# CTRL_MMR0_CFG0 register map
Vendor: Texas Instruments
Peripheral module from a debugger description file (folder am243x).
Registers are 32-bit, read-write, reset 0x0 unless marked. A register's access mark holds for its fields unless they carry their own. Offsets are as the file gives them; lines under a group give offsets from that group; [hi:lo] are bit positions; {n}, {i} and the like mark numbered series; 'fields as' and 'values as' point back to an identical list; <NAME> marks a mode.

## CTRL_MMR0_CFG0
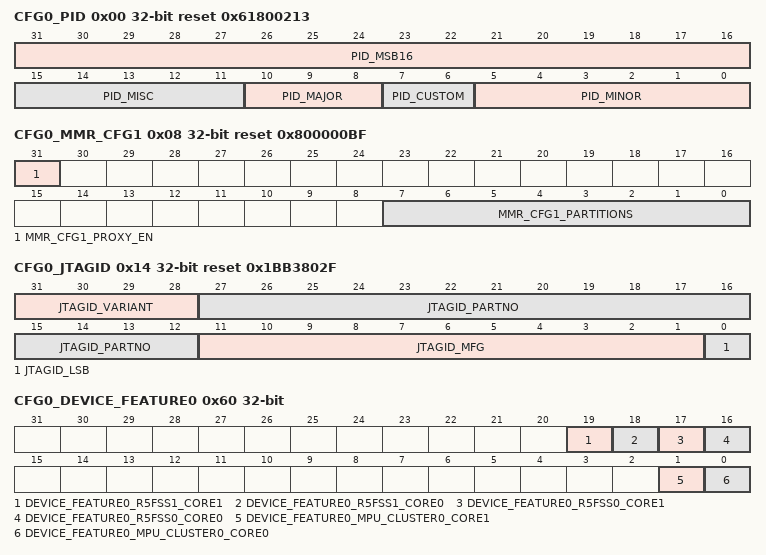
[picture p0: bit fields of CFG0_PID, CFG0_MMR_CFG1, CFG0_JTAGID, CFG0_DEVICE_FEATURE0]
0x00 CFG0_PID ro reset 0x61800213
  [31:16] PID_MSB16, [15:11] PID_MISC, [10:8] PID_MAJOR, [7:6] PID_CUSTOM, [5:0] PID_MINOR
0x08 CFG0_MMR_CFG1 ro reset 0x800000BF
  [31] MMR_CFG1_PROXY_EN — Proxy addressing activated
  [7:0] MMR_CFG1_PARTITIONS — Indicates present partitions
0x14 CFG0_JTAGID ro reset 0x1BB3802F
  [31:28] JTAGID_VARIANT — Used to indicate new PGs
  [27:12] JTAGID_PARTNO — Part number for boundary scan
  [11:1] JTAGID_MFG — Indicates manufacturer
  [0] JTAGID_LSB — Always 1
0x18 CFG0_JTAG_USER_ID ro
  [31:0] JTAG_USER_ID_USERCODE — Device information
0x30 CFG0_MAIN_DEVSTAT
  [15:0] MAIN_DEVSTAT_BOOTMODE — Specifies the device Primary and Backup boot media.
0x34 CFG0_MAIN_BOOTCFG ro
  [15:0] MAIN_BOOTCFG_BOOTMODE — Specifies the device Primary and Backup boot media as latched at PORz
0x44 CFG0_BOOT_PROGRESS
  [31:0] BOOT_PROGRESS_PROGRESS — Written by ROM to indicate boot progression. Values and their meaning are determined by the ROM.
0x60 CFG0_DEVICE_FEATURE0 ro
  [19] DEVICE_FEATURE0_R5FSS1_CORE1 — R5FSS1 CPU1 activated when set. CPU0 must also be activated.
  [18] DEVICE_FEATURE0_R5FSS1_CORE0 — R5FSS1 CPU0 activated when set.
  [17] DEVICE_FEATURE0_R5FSS0_CORE1 — R5FSS0 CPU1 activated when set. CPU0 must also be activated.
  [16] DEVICE_FEATURE0_R5FSS0_CORE0 — R5FSS0 CPU0 activated when set.
  [1] DEVICE_FEATURE0_MPU_CLUSTER0_CORE1 — MPU Cluster0 Core 1 is activated when set
  [0] DEVICE_FEATURE0_MPU_CLUSTER0_CORE0 — MPU Cluster0 Core 0 is activated when set
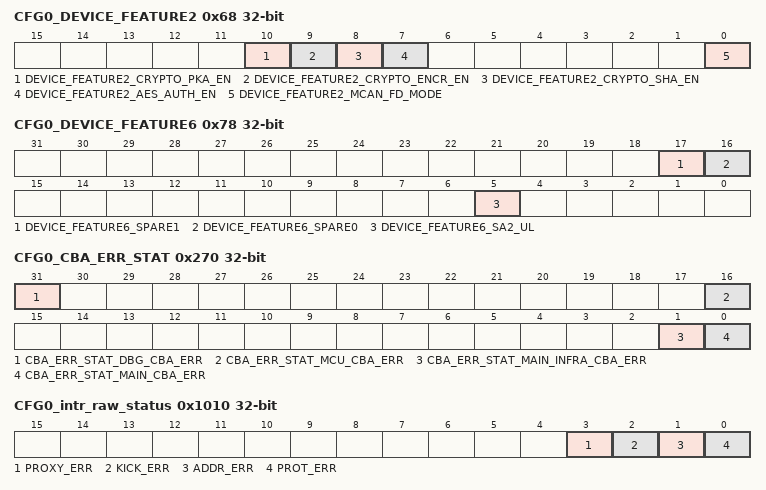
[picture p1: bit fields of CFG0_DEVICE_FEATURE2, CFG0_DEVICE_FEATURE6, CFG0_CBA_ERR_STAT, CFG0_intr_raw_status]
0x68 CFG0_DEVICE_FEATURE2 ro
  [10] DEVICE_FEATURE2_CRYPTO_PKA_EN — SA2_UL Crypto Module PKA activated
  [9] DEVICE_FEATURE2_CRYPTO_ENCR_EN — SA2_UL Crypto Module AES/3DES/DBRG activated
  [8] DEVICE_FEATURE2_CRYPTO_SHA_EN — SA2_UL Crypto Module SHA/MD5 activated
  [7] DEVICE_FEATURE2_AES_AUTH_EN — AES authentication is activated in FlashSS and DMSC when set
  [0] DEVICE_FEATURE2_MCAN_FD_MODE — FD mode is supported on MCAN[1:0] when set
0x78 CFG0_DEVICE_FEATURE6 access not given
  [17] DEVICE_FEATURE6_SPARE1 ro — Spare1 LPSC is activated when set
  [16] DEVICE_FEATURE6_SPARE0 ro — Spare0 LPSC is activated when set
  [5] DEVICE_FEATURE6_SA2_UL ro — MAIN domain security accelerator is activated when set
0x200 CFG0_MAC_ID0
  [31:0] MAC_ID0_MACID_LO — 32 lsbs of MAC address
0x204 CFG0_MAC_ID1
  [15:0] MAC_ID1_MACID_HI — 16 msbs of MAC address
0x210 CFG0_PCI_DEVICE_ID0 reset 0xB010104C
  [31:0] PCI_DEVICE_ID0_ID0 — ROM can optionally update this register with a 32 bit value from Customer OTP.
0x214 CFG0_PCI_DEVICE_ID1 reset 0xB010104C
  [31:0] PCI_DEVICE_ID1_ID1 — ROM can optionally update this register with a 32 bit value from Customer OTP.
0x220 CFG0_USB_DEVICE_ID0 reset 0x61650451
  [31:0] USB_DEVICE_ID0_ID0 — ROM can optionally update this register with a 32 bit value from Customer OTP.
0x224 CFG0_USB_DEVICE_ID1 reset 0x61650451
  [31:0] USB_DEVICE_ID1_ID1 — ROM can optionally update this register with a 32 bit value from Customer OTP.
{0x230+4i} CFG0_GP_SW{i} ro (i=0..2)
  [31:0] GP_SW{i}_VAL — general purpose value
0x23C CFG0_GP_SW3 ro
  [3:0] GP_SW3_VAL — general purpose value
0x270 CFG0_CBA_ERR_STAT ro
  [31] CBA_ERR_STAT_DBG_CBA_ERR, [16] CBA_ERR_STAT_MCU_CBA_ERR, [1] CBA_ERR_STAT_MAIN_INFRA_CBA_ERR, [0] CBA_ERR_STAT_MAIN_CBA_ERR
{0x1008+0x4000*i} CFG0_LOCK{i}_KICK0 (i=0..6)
  [31:0] LOCK{i}_KICK0 — - KICK0 component
{0x100C+0x4000*i} CFG0_LOCK{i}_KICK1 (i=0..6)
  [31:0] LOCK{i}_KICK1 — - KICK1 component
0x1010 CFG0_intr_raw_status access not given
  [3] PROXY_ERR — Proxy0 access violation error. Raw status is read. Write a 1 to set the status. Writing a 0 has no effect. (access R/W1TS)
  [2] KICK_ERR — Kick access violation error. Raw status is read. Write a 1 to set the status. Writing a 0 has no effect. (access R/W1TS)
  [1] ADDR_ERR — Addressing violation error. Raw status is read. Write a 1 to set the status. Writing a 0 has no effect. (access R/W1TS)
  [0] PROT_ERR — Protection violation error. Raw status is read. Write a 1 to set the status. Writing a 0 has no effect. (access R/W1TS)
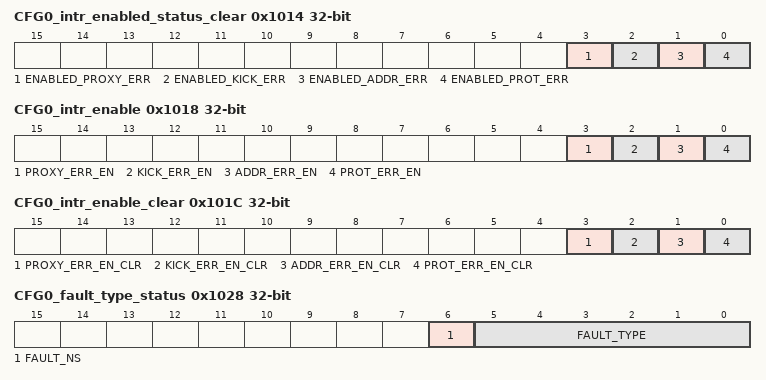
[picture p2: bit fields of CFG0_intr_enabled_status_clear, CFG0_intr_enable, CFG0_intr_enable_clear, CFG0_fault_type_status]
0x1014 CFG0_intr_enabled_status_clear access not given
  [3] ENABLED_PROXY_ERR — Proxy0 access violation error. Enabled status is read. Write a 1 to clear the status. Writing a 0 has no effect. (access R/W1TC)
  [2] ENABLED_KICK_ERR — Kick access violation error. Enabled status is read. Write a 1 to clear the status. Writing a 0 has no effect. (access R/W1TC)
  [1] ENABLED_ADDR_ERR — Addressing violation error. Enabled status is read. Write a 1 to clear the status. Writing a 0 has no effect. (access R/W1TC)
  [0] ENABLED_PROT_ERR — Protection violation error. Enabled status is read. Write a 1 to clear the status. Writing a 0 has no effect. (access R/W1TC)
0x1018 CFG0_intr_enable access not given
  [3] PROXY_ERR_EN — Proxy0 access violation error enable. Write a 1 to set the enable. Writing a 0 has no effect. (access R/W1TS)
  [2] KICK_ERR_EN — Kick access violation error enable. Write a 1 to set the enable. Writing a 0 has no effect. (access R/W1TS)
  [1] ADDR_ERR_EN — Addressing violation error enable. Write a 1 to set the enable. Writing a 0 has no effect. (access R/W1TS)
  [0] PROT_ERR_EN — Protection violation error enable. Write a 1 to set the enable. Writing a 0 has no effect. (access R/W1TS)
0x101C CFG0_intr_enable_clear access not given
  [3] PROXY_ERR_EN_CLR — Proxy0 access violation error enable clear. Write a 1 to clear the enable. Writing a 0 has no effect. (access R/W1TC)
  [2] KICK_ERR_EN_CLR — Kick access violation error enable clear. Write a 1 to clear the enable. Writing a 0 has no effect. (access R/W1TC)
  [1] ADDR_ERR_EN_CLR — Addressing violation error enable clear. Write a 1 to clear the enable. Writing a 0 has no effect. (access R/W1TC)
  [0] PROT_ERR_EN_CLR — Protection violation error enable clear. Write a 1 to clear the enable. Writing a 0 has no effect. (access R/W1TC)
0x1020 CFG0_eoi
  [7:0] EOI_VECTOR — EOI vector value. Write this with interrupt distribution value in the chip.
0x1024 CFG0_fault_address ro
  [31:0] FAULT_ADDR — Fault Address.
0x1028 CFG0_fault_type_status ro
  [6] FAULT_NS — Non-secure access.
  [5:0] FAULT_TYPE — Fault Type 10_0000 = Supervisor read fault - priv = 1 dir = 1 dtype != 1 01_0000 = Supervisor write fault - priv = 1 dir = 0 00_1000 = Supervisor execute fault - priv = 1 dir = 1 dtype = 1 00_0100 = User read fault - priv = 0 dir = 1 dtype = 1 00_0010 = User write fault - priv = 0 dir = 0 00_0001 = User execute fault - priv = 0 dir = 1 dtype = 1 00_0000 = No fault
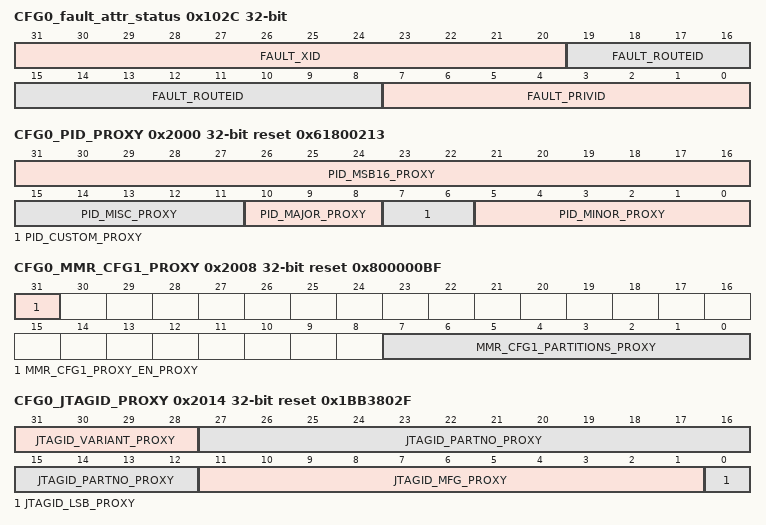
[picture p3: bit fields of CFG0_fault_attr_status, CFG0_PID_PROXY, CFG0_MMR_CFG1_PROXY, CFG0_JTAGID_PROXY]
0x102C CFG0_fault_attr_status ro
  [31:20] FAULT_XID — XID.
  [19:8] FAULT_ROUTEID — Route ID.
  [7:0] FAULT_PRIVID — Privilege ID.
0x1030 CFG0_fault_clear wo
  [0] FAULT_CLR — Fault clear. Writing a 1 clears the current fault. Writing a 0 has no effect.
{0x1100+4i} CFG0_CLAIMREG_P0_R{i}_READONLY ro (i=0..6)
  [31:0] CLAIMREG_P0_R{i}_READONLY — Claim bits for Partition 0
0x2000 CFG0_PID_PROXY ro reset 0x61800213
  [31:16] PID_MSB16_PROXY, [15:11] PID_MISC_PROXY, [10:8] PID_MAJOR_PROXY, [7:6] PID_CUSTOM_PROXY, [5:0] PID_MINOR_PROXY
0x2008 CFG0_MMR_CFG1_PROXY ro reset 0x800000BF
  [31] MMR_CFG1_PROXY_EN_PROXY — Proxy addressing activated
  [7:0] MMR_CFG1_PARTITIONS_PROXY — Indicates present partitions
0x2014 CFG0_JTAGID_PROXY ro reset 0x1BB3802F
  [31:28] JTAGID_VARIANT_PROXY — Used to indicate new PGs
  [27:12] JTAGID_PARTNO_PROXY — Part number for boundary scan
  [11:1] JTAGID_MFG_PROXY — Indicates manufacturer
  [0] JTAGID_LSB_PROXY — Always 1
0x2018 CFG0_JTAG_USER_ID_PROXY ro
  [31:0] JTAG_USER_ID_USERCODE_PROXY — Device information
0x2030 CFG0_MAIN_DEVSTAT_PROXY
  [15:0] MAIN_DEVSTAT_BOOTMODE_PROXY — Specifies the device Primary and Backup boot media.
0x2034 CFG0_MAIN_BOOTCFG_PROXY ro
  [15:0] MAIN_BOOTCFG_BOOTMODE_PROXY — Specifies the device Primary and Backup boot media as latched at PORz
0x2044 CFG0_BOOT_PROGRESS_PROXY
  [31:0] BOOT_PROGRESS_PROGRESS_PROXY — Written by ROM to indicate boot progression. Values and their meaning are determined by the ROM.
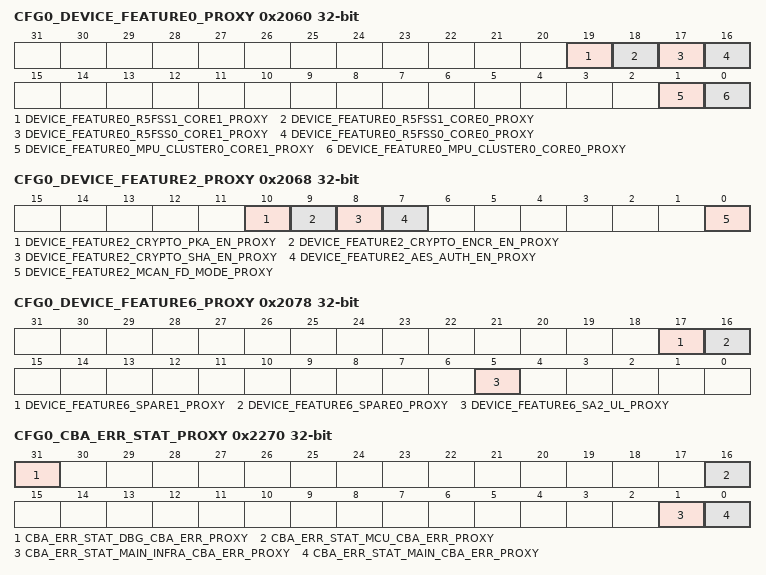
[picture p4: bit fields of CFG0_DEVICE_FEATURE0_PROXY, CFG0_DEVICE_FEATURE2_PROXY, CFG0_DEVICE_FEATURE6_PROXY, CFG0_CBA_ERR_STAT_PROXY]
0x2060 CFG0_DEVICE_FEATURE0_PROXY ro
  [19] DEVICE_FEATURE0_R5FSS1_CORE1_PROXY — R5FSS1 CPU1 activated when set. CPU0 must also be activated.
  [18] DEVICE_FEATURE0_R5FSS1_CORE0_PROXY — R5FSS1 CPU0 activated when set.
  [17] DEVICE_FEATURE0_R5FSS0_CORE1_PROXY — R5FSS0 CPU1 activated when set. CPU0 must also be activated.
  [16] DEVICE_FEATURE0_R5FSS0_CORE0_PROXY — R5FSS0 CPU0 activated when set.
  [1] DEVICE_FEATURE0_MPU_CLUSTER0_CORE1_PROXY — MPU Cluster0 Core 1 is activated when set
  [0] DEVICE_FEATURE0_MPU_CLUSTER0_CORE0_PROXY — MPU Cluster0 Core 0 is activated when set
0x2068 CFG0_DEVICE_FEATURE2_PROXY ro
  [10] DEVICE_FEATURE2_CRYPTO_PKA_EN_PROXY — SA2_UL Crypto Module PKA activated
  [9] DEVICE_FEATURE2_CRYPTO_ENCR_EN_PROXY — SA2_UL Crypto Module AES/3DES/DBRG activated
  [8] DEVICE_FEATURE2_CRYPTO_SHA_EN_PROXY — SA2_UL Crypto Module SHA/MD5 activated
  [7] DEVICE_FEATURE2_AES_AUTH_EN_PROXY — AES authentication is activated in FlashSS and DMSC when set
  [0] DEVICE_FEATURE2_MCAN_FD_MODE_PROXY — FD mode is supported on MCAN[1:0] when set
0x2078 CFG0_DEVICE_FEATURE6_PROXY access not given
  [17] DEVICE_FEATURE6_SPARE1_PROXY ro — Spare1 LPSC is activated when set
  [16] DEVICE_FEATURE6_SPARE0_PROXY ro — Spare0 LPSC is activated when set
  [5] DEVICE_FEATURE6_SA2_UL_PROXY ro — MAIN domain security accelerator is activated when set
0x2200 CFG0_MAC_ID0_PROXY
  [31:0] MAC_ID0_MACID_LO_PROXY — 32 lsbs of MAC address
0x2204 CFG0_MAC_ID1_PROXY
  [15:0] MAC_ID1_MACID_HI_PROXY — 16 msbs of MAC address
0x2210 CFG0_PCI_DEVICE_ID0_PROXY reset 0xB010104C
  [31:0] PCI_DEVICE_ID0_ID0_PROXY — ROM can optionally update this register with a 32 bit value from Customer OTP.
0x2214 CFG0_PCI_DEVICE_ID1_PROXY reset 0xB010104C
  [31:0] PCI_DEVICE_ID1_ID1_PROXY — ROM can optionally update this register with a 32 bit value from Customer OTP.
0x2220 CFG0_USB_DEVICE_ID0_PROXY reset 0x61650451
  [31:0] USB_DEVICE_ID0_ID0_PROXY — ROM can optionally update this register with a 32 bit value from Customer OTP.
0x2224 CFG0_USB_DEVICE_ID1_PROXY reset 0x61650451
  [31:0] USB_DEVICE_ID1_ID1_PROXY — ROM can optionally update this register with a 32 bit value from Customer OTP.
{0x2230+4i} CFG0_GP_SW{i}_PROXY ro (i=0..2)
  [31:0] GP_SW{i}_VAL_PROXY — general purpose value
0x223C CFG0_GP_SW3_PROXY ro
  [3:0] GP_SW3_VAL_PROXY — general purpose value
0x2270 CFG0_CBA_ERR_STAT_PROXY ro
  [31] CBA_ERR_STAT_DBG_CBA_ERR_PROXY, [16] CBA_ERR_STAT_MCU_CBA_ERR_PROXY, [1] CBA_ERR_STAT_MAIN_INFRA_CBA_ERR_PROXY, [0] CBA_ERR_STAT_MAIN_CBA_ERR_PROXY
{0x3008+0x4000*i} CFG0_LOCK{i}_KICK0_PROXY (i=0..6)
  [31:0] LOCK{i}_KICK0_PROXY — - KICK0 component
{0x300C+0x4000*i} CFG0_LOCK{i}_KICK1_PROXY (i=0..6)
  [31:0] LOCK{i}_KICK1_PROXY — - KICK1 component
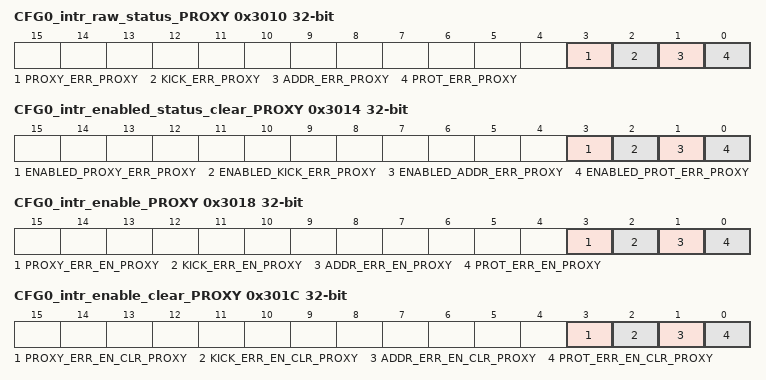
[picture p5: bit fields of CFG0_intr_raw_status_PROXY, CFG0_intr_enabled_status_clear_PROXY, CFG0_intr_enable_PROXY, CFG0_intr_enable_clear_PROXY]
0x3010 CFG0_intr_raw_status_PROXY access not given
  [3] PROXY_ERR_PROXY — Proxy0 access violation error. Raw status is read. Write a 1 to set the status. Writing a 0 has no effect. (access R/W1TS)
  [2] KICK_ERR_PROXY — Kick access violation error. Raw status is read. Write a 1 to set the status. Writing a 0 has no effect. (access R/W1TS)
  [1] ADDR_ERR_PROXY — Addressing violation error. Raw status is read. Write a 1 to set the status. Writing a 0 has no effect. (access R/W1TS)
  [0] PROT_ERR_PROXY — Protection violation error. Raw status is read. Write a 1 to set the status. Writing a 0 has no effect. (access R/W1TS)
0x3014 CFG0_intr_enabled_status_clear_PROXY access not given
  [3] ENABLED_PROXY_ERR_PROXY — Proxy0 access violation error. Enabled status is read. Write a 1 to clear the status. Writing a 0 has no effect. (access R/W1TC)
  [2] ENABLED_KICK_ERR_PROXY — Kick access violation error. Enabled status is read. Write a 1 to clear the status. Writing a 0 has no effect. (access R/W1TC)
  [1] ENABLED_ADDR_ERR_PROXY — Addressing violation error. Enabled status is read. Write a 1 to clear the status. Writing a 0 has no effect. (access R/W1TC)
  [0] ENABLED_PROT_ERR_PROXY — Protection violation error. Enabled status is read. Write a 1 to clear the status. Writing a 0 has no effect. (access R/W1TC)
0x3018 CFG0_intr_enable_PROXY access not given
  [3] PROXY_ERR_EN_PROXY — Proxy0 access violation error enable. Write a 1 to set the enable. Writing a 0 has no effect. (access R/W1TS)
  [2] KICK_ERR_EN_PROXY — Kick access violation error enable. Write a 1 to set the enable. Writing a 0 has no effect. (access R/W1TS)
  [1] ADDR_ERR_EN_PROXY — Addressing violation error enable. Write a 1 to set the enable. Writing a 0 has no effect. (access R/W1TS)
  [0] PROT_ERR_EN_PROXY — Protection violation error enable. Write a 1 to set the enable. Writing a 0 has no effect. (access R/W1TS)
0x301C CFG0_intr_enable_clear_PROXY access not given
  [3] PROXY_ERR_EN_CLR_PROXY — Proxy0 access violation error enable clear. Write a 1 to clear the enable. Writing a 0 has no effect. (access R/W1TC)
  [2] KICK_ERR_EN_CLR_PROXY — Kick access violation error enable clear. Write a 1 to clear the enable. Writing a 0 has no effect. (access R/W1TC)
  [1] ADDR_ERR_EN_CLR_PROXY — Addressing violation error enable clear. Write a 1 to clear the enable. Writing a 0 has no effect. (access R/W1TC)
  [0] PROT_ERR_EN_CLR_PROXY — Protection violation error enable clear. Write a 1 to clear the enable. Writing a 0 has no effect. (access R/W1TC)
0x3020 CFG0_eoi_PROXY
  [7:0] EOI_VECTOR_PROXY — EOI vector value. Write this with interrupt distribution value in the chip.
0x3024 CFG0_fault_address_PROXY ro
  [31:0] FAULT_ADDR_PROXY — Fault Address.
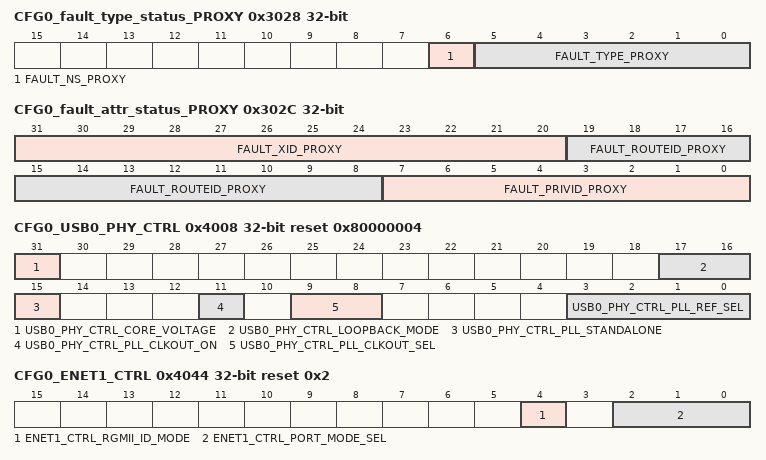
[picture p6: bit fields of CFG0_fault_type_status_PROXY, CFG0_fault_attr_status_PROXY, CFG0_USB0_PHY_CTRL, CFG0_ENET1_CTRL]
0x3028 CFG0_fault_type_status_PROXY ro
  [6] FAULT_NS_PROXY — Non-secure access.
  [5:0] FAULT_TYPE_PROXY — Fault Type 10_0000 = Supervisor read fault - priv = 1 dir = 1 dtype != 1 01_0000 = Supervisor write fault - priv = 1 dir = 0 00_1000 = Supervisor execute fault - priv = 1 dir = 1 dtype = 1 00_0100 = User read fault - priv = 0 dir = 1 dtype = 1 00_0010 = User write fault - priv = 0 dir = 0 00_0001 = User execute fault - priv = 0 dir = 1 dtype = 1 00_0000 = No fault
0x302C CFG0_fault_attr_status_PROXY ro
  [31:20] FAULT_XID_PROXY — XID.
  [19:8] FAULT_ROUTEID_PROXY — Route ID.
  [7:0] FAULT_PRIVID_PROXY — Privilege ID.
0x3030 CFG0_fault_clear_PROXY wo
  [0] FAULT_CLR_PROXY — Fault clear. Writing a 1 clears the current fault. Writing a 0 has no effect.
{0x3100+4i} CFG0_CLAIMREG_P0_R{i} (i=0..6)
  [31:0] CLAIMREG_P0_R{i} — Claim bits for Partition 0
0x4008 CFG0_USB0_PHY_CTRL reset 0x80000004
  [31] USB0_PHY_CTRL_CORE_VOLTAGE — Selects the USB PHY Core Voltage
  [17:16] USB0_PHY_CTRL_LOOPBACK_MODE — Activates USB0 PHY loopback operation
  [15] USB0_PHY_CTRL_PLL_STANDALONE — Activates USB0 PHY as a standalone PLL
  [11] USB0_PHY_CTRL_PLL_CLKOUT_ON — Controls USB0 PLL clock output
  [9:8] USB0_PHY_CTRL_PLL_CLKOUT_SEL — Selects the frequency of the USB0 PLL output clock
  [3:0] USB0_PHY_CTRL_PLL_REF_SEL — Indicates the frequency of the REF_CLOCK input used by the USB PLL. This value should match the frequency value of either the HFOSC0 or HFOSC1 oscillator as selected by the USB0_CLKSEL register
0x4044 CFG0_ENET1_CTRL reset 0x2
  [4] ENET1_CTRL_RGMII_ID_MODE — Port1 RGMII internal transmit delay selection
  [2:0] ENET1_CTRL_PORT_MODE_SEL — Selects Ethernet switch Port1 interface
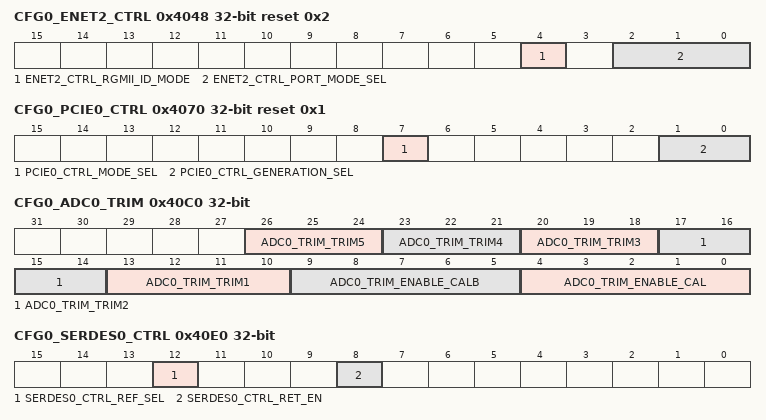
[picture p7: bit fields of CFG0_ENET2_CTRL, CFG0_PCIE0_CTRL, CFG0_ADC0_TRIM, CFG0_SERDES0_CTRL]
0x4048 CFG0_ENET2_CTRL reset 0x2
  [4] ENET2_CTRL_RGMII_ID_MODE — Port2 RGMII internal transmit delay selection
  [2:0] ENET2_CTRL_PORT_MODE_SEL — Selects Ethernet switch Port2 interface
0x4070 CFG0_PCIE0_CTRL reset 0x1
  [7] PCIE0_CTRL_MODE_SEL — Selects the operating mode
  [1:0] PCIE0_CTRL_GENERATION_SEL — Configures the PCIe generation support in the PCIe capabilities linked-list
0x4080 CFG0_SERDES0_LN0_CTRL
  [1:0] SERDES0_LN0_CTRL_LANE_FUNC_SEL — Selects the SERDES0 lane0 function
0x40C0 CFG0_ADC0_TRIM
  [26:24] ADC0_TRIM_TRIM5 — Trims Nonlinearities from ADC
  [23:21] ADC0_TRIM_TRIM4 — Trims Nonlinearities from ADC
  [20:18] ADC0_TRIM_TRIM3 — Trims Nonlinearities from ADC
  [17:14] ADC0_TRIM_TRIM2 — Trims Nonlinearities from ADC
  [13:10] ADC0_TRIM_TRIM1 — Trims Nonlinearities from ADC
  [9:5] ADC0_TRIM_ENABLE_CALB — Trims Nonlinearities from ADC
  [4:0] ADC0_TRIM_ENABLE_CAL — Trims Nonlinearities from ADC
0x40E0 CFG0_SERDES0_CTRL
  [12] SERDES0_CTRL_REF_SEL — REFCLK output select
  [8] SERDES0_CTRL_RET_EN — Retention activate
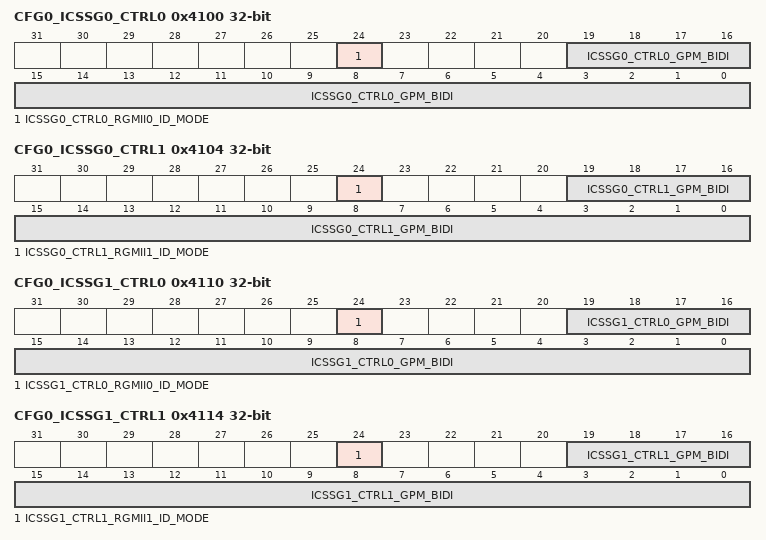
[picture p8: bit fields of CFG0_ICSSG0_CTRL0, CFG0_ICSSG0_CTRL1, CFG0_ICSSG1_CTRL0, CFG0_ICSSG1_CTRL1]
0x4100 CFG0_ICSSG0_CTRL0
  [24] ICSSG0_CTRL0_RGMII0_ID_MODE — Controls the ICSS_G0 RGMII0 port internal transmit delay
  [19:0] ICSSG0_CTRL0_GPM_BIDI — Controls operation of the ICSS_G0 PRU0_GPO pins. Each bit n controls the corresponding PRG0_PRU0GPOn I/O
0x4104 CFG0_ICSSG0_CTRL1
  [24] ICSSG0_CTRL1_RGMII1_ID_MODE — Controls the ICSS_G0 RGMII1 port internal transmit delay
  [19:0] ICSSG0_CTRL1_GPM_BIDI — Controls operation of the ICSS_G0 PRU1_GPO pins. Each bit n controls the corresponding PRG0_PRU1GPOn I/O
0x4110 CFG0_ICSSG1_CTRL0
  [24] ICSSG1_CTRL0_RGMII0_ID_MODE — Controls the ICSS_G1 RGMII0 port internal transmit delay
  [19:0] ICSSG1_CTRL0_GPM_BIDI — Controls operation of the ICSS_G1 PRU0_GPO pins. Each bit n controls the corresponding PRG1_PRU0GPOn I/O
0x4114 CFG0_ICSSG1_CTRL1
  [24] ICSSG1_CTRL1_RGMII1_ID_MODE — Controls the ICSS_G1 RGMII1 port internal transmit delay
  [19:0] ICSSG1_CTRL1_GPM_BIDI — Controls operation of the ICSS_G1 PRU1_GPO pins. Each bit n controls the corresponding PRG1_PRU1GPOn I/O
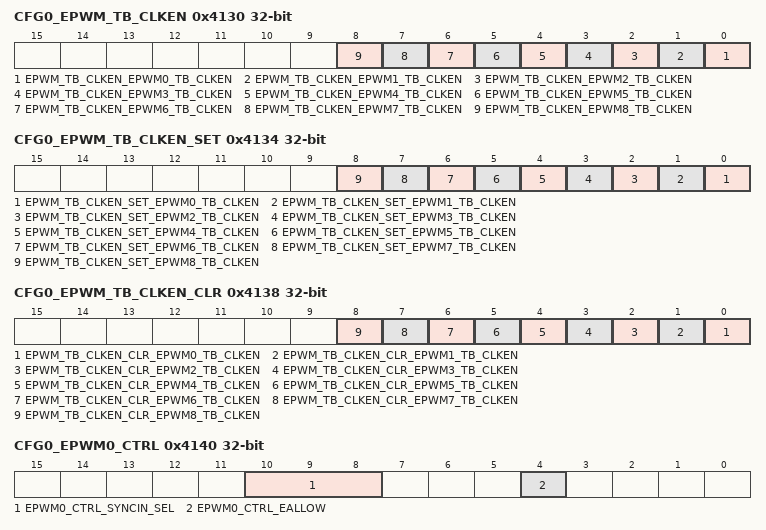
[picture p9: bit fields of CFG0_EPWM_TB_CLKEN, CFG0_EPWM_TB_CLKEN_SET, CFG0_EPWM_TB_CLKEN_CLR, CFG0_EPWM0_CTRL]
0x4130 CFG0_EPWM_TB_CLKEN
  [n] EPWM_TB_CLKEN_EPWM{n}_TB_CLKEN (n=0..8) — Activates Timebase Clock of EPWM{n} When Set
0x4134 CFG0_EPWM_TB_CLKEN_SET access not given
  [n] EPWM_TB_CLKEN_SET_EPWM{n}_TB_CLKEN (n=0..8) — Writing One Activates Timebase Clock of EPWM{n} (access R/W1TS)
0x4138 CFG0_EPWM_TB_CLKEN_CLR access not given
  [n] EPWM_TB_CLKEN_CLR_EPWM{n}_TB_CLKEN (n=0..8) — Writing One Deactivates Timebase Clock of EPWM{n} (access R/W1TC)
0x4140 CFG0_EPWM0_CTRL
  [10:8] EPWM0_CTRL_SYNCIN_SEL — Selects the source of the EPWM0 synchronization input
  [4] EPWM0_CTRL_EALLOW — Activate write access to EPWM tripzone registers
0x4144 CFG0_EPWM1_CTRL
  [4] EPWM1_CTRL_EALLOW — Activate write access to EPWM tripzone registers
0x4148 CFG0_EPWM2_CTRL
  [4] EPWM2_CTRL_EALLOW — Activate write access to EPWM tripzone registers
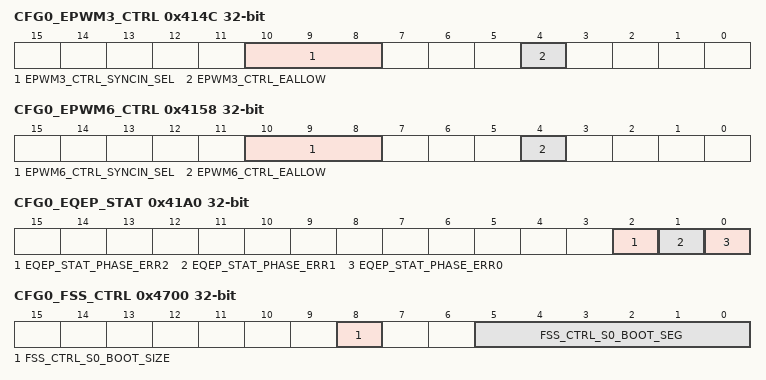
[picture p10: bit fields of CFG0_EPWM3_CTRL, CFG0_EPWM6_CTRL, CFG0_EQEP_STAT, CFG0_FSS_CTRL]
0x414C CFG0_EPWM3_CTRL
  [10:8] EPWM3_CTRL_SYNCIN_SEL — Selects the source of the EPWM3 synchronization input
  [4] EPWM3_CTRL_EALLOW — Activate write access to EPWM tripzone registers
0x4150 CFG0_EPWM4_CTRL
  [4] EPWM4_CTRL_EALLOW — Activate write access to EPWM tripzone registers
0x4154 CFG0_EPWM5_CTRL
  [4] EPWM5_CTRL_EALLOW — Activate write access to EPWM tripzone registers
0x4158 CFG0_EPWM6_CTRL
  [10:8] EPWM6_CTRL_SYNCIN_SEL — Selects the source of the EPWM6 synchronization input
  [4] EPWM6_CTRL_EALLOW — Activate write access to EPWM tripzone registers
0x415C CFG0_EPWM7_CTRL
  [4] EPWM7_CTRL_EALLOW — Activate write access to EPWM tripzone registers
0x4160 CFG0_EPWM8_CTRL
  [4] EPWM8_CTRL_EALLOW — Activate write access to EPWM tripzone registers
0x4170 CFG0_SOCA_SEL
  [1:0] SOCA_SEL_SOCA_SEL — Selects the SOC A output source
0x4174 CFG0_SOCB_SEL
  [1:0] SOCB_SEL_SOCB_SEL — Selects the SOC B output source
{0x4180+4i} CFG0_EQEP{i}_CTRL (i=0..2)
  [4:0] EQEP{i}_CTRL_SOCA_SEL — Selects the source of SOCA input for EQEP{i}
0x41A0 CFG0_EQEP_STAT ro
  [2] EQEP_STAT_PHASE_ERR2 — EQEP2 Phase error status
  [1] EQEP_STAT_PHASE_ERR1 — EQEP1 Phase error status
  [0] EQEP_STAT_PHASE_ERR0 — EQEP0 Phase error status
0x41B4 CFG0_SDIO1_CTRL
  [4:0] SDIO1_CTRL_DRV_STR — Selects the SDIO drive strength
0x4204 CFG0_TIMER1_CTRL
  [8] TIMER1_CTRL_CASCADE_EN — Activates cascading of TIMER1 to TIMER0
0x420C CFG0_TIMER3_CTRL
  [8] TIMER3_CTRL_CASCADE_EN — Activates cascading of TIMER3 to TIMER2
0x4214 CFG0_TIMER5_CTRL
  [8] TIMER5_CTRL_CASCADE_EN — Activates cascading of TIMER5 to TIMER4
0x421C CFG0_TIMER7_CTRL
  [8] TIMER7_CTRL_CASCADE_EN — Activates cascading of TIMER7 to TIMER6
0x4224 CFG0_TIMER9_CTRL
  [8] TIMER9_CTRL_CASCADE_EN — Activates cascading of TIMER9 to TIMER8
0x422C CFG0_TIMER11_CTRL
  [8] TIMER11_CTRL_CASCADE_EN — Activates cascading of TIMER11 to TIMER10
0x42E0 CFG0_I2C0_CTRL
  [0] I2C0_CTRL_HS_MCS_EN — HS Mode controller current source activate.
0x4700 CFG0_FSS_CTRL
  [8] FSS_CTRL_S0_BOOT_SIZE — Selects the size of the boot block to be used for the S0 (OSPI0) flash interface
  [5:0] FSS_CTRL_S0_BOOT_SEG — Selects the boot block to be used for the S0 (OSPI0) flash interface. If the s0_boot_size is 128 MB then only bits [4:0] of this field are used. Care must be taken to account for the address translation as to not fall off or wrap the address of the flash. (e.g. if both ECC and authentication are activated for 64 MB boot, the highest valid block number is is 49, as sector 50 is only .2M Bytes in size.)
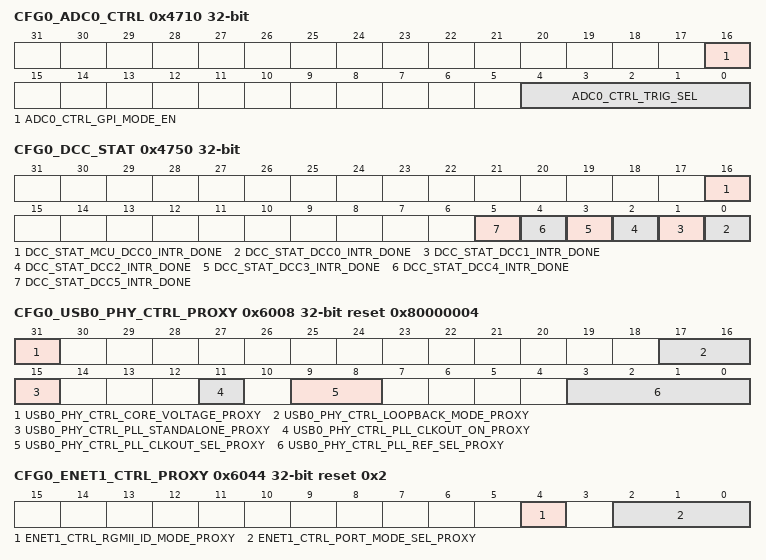
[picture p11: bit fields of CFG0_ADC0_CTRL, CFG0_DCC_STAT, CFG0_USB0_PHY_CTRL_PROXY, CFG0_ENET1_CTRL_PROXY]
0x4710 CFG0_ADC0_CTRL
  [16] ADC0_CTRL_GPI_MODE_EN — Activates ADC0 data pins to be used as general purpose inputs when set. This signal is tied to the en_dig_test input of MCU_ADC0
  [4:0] ADC0_CTRL_TRIG_SEL — Selects the source of the ADC hardware event trigger
0x4750 CFG0_DCC_STAT ro
  [16] DCC_STAT_MCU_DCC0_INTR_DONE — MCU_DCC0 Done Interrupt Status
  [n] DCC_STAT_DCC{n}_INTR_DONE (n=0..5) — DCC{n} Done Interrupt Status
{0x5100+4i} CFG0_CLAIMREG_P1_R{i}_READONLY ro (i=0..14)
  [31:0] CLAIMREG_P1_R{i}_READONLY — Claim bits for Partition 1
0x6008 CFG0_USB0_PHY_CTRL_PROXY reset 0x80000004
  [31] USB0_PHY_CTRL_CORE_VOLTAGE_PROXY — Selects the USB PHY Core Voltage
  [17:16] USB0_PHY_CTRL_LOOPBACK_MODE_PROXY — Activates USB0 PHY loopback operation
  [15] USB0_PHY_CTRL_PLL_STANDALONE_PROXY — Activates USB0 PHY as a standalone PLL
  [11] USB0_PHY_CTRL_PLL_CLKOUT_ON_PROXY — Controls USB0 PLL clock output
  [9:8] USB0_PHY_CTRL_PLL_CLKOUT_SEL_PROXY — Selects the frequency of the USB0 PLL output clock
  [3:0] USB0_PHY_CTRL_PLL_REF_SEL_PROXY — Indicates the frequency of the REF_CLOCK input used by the USB PLL. This value should match the frequency value of either the HFOSC0 or HFOSC1 oscillator as selected by the USB0_CLKSEL register
0x6044 CFG0_ENET1_CTRL_PROXY reset 0x2
  [4] ENET1_CTRL_RGMII_ID_MODE_PROXY — Port1 RGMII internal transmit delay selection
  [2:0] ENET1_CTRL_PORT_MODE_SEL_PROXY — Selects Ethernet switch Port1 interface
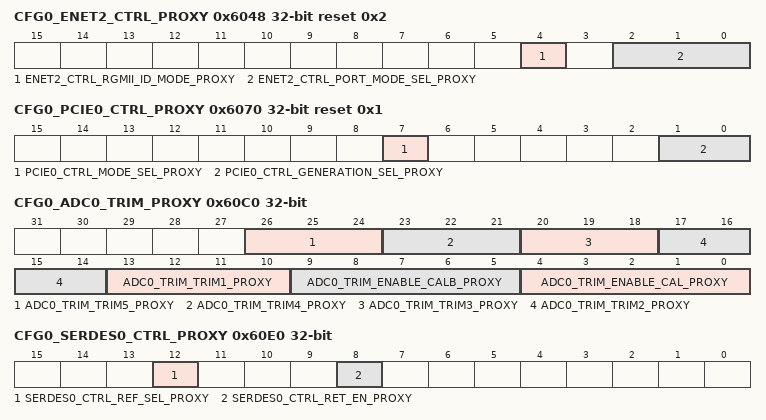
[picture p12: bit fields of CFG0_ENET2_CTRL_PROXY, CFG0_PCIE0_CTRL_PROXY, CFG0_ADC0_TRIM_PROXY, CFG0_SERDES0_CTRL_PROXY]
0x6048 CFG0_ENET2_CTRL_PROXY reset 0x2
  [4] ENET2_CTRL_RGMII_ID_MODE_PROXY — Port2 RGMII internal transmit delay selection
  [2:0] ENET2_CTRL_PORT_MODE_SEL_PROXY — Selects Ethernet switch Port2 interface
0x6070 CFG0_PCIE0_CTRL_PROXY reset 0x1
  [7] PCIE0_CTRL_MODE_SEL_PROXY — Selects the operating mode
  [1:0] PCIE0_CTRL_GENERATION_SEL_PROXY — Configures the PCIe generation support in the PCIe capabilities linked-list
0x6080 CFG0_SERDES0_LN0_CTRL_PROXY
  [1:0] SERDES0_LN0_CTRL_LANE_FUNC_SEL_PROXY — Selects the SERDES0 lane0 function
0x60C0 CFG0_ADC0_TRIM_PROXY
  [26:24] ADC0_TRIM_TRIM5_PROXY — Trims Nonlinearities from ADC
  [23:21] ADC0_TRIM_TRIM4_PROXY — Trims Nonlinearities from ADC
  [20:18] ADC0_TRIM_TRIM3_PROXY — Trims Nonlinearities from ADC
  [17:14] ADC0_TRIM_TRIM2_PROXY — Trims Nonlinearities from ADC
  [13:10] ADC0_TRIM_TRIM1_PROXY — Trims Nonlinearities from ADC
  [9:5] ADC0_TRIM_ENABLE_CALB_PROXY — Trims Nonlinearities from ADC
  [4:0] ADC0_TRIM_ENABLE_CAL_PROXY — Trims Nonlinearities from ADC
0x60E0 CFG0_SERDES0_CTRL_PROXY
  [12] SERDES0_CTRL_REF_SEL_PROXY — REFCLK output select
  [8] SERDES0_CTRL_RET_EN_PROXY — Retention activate
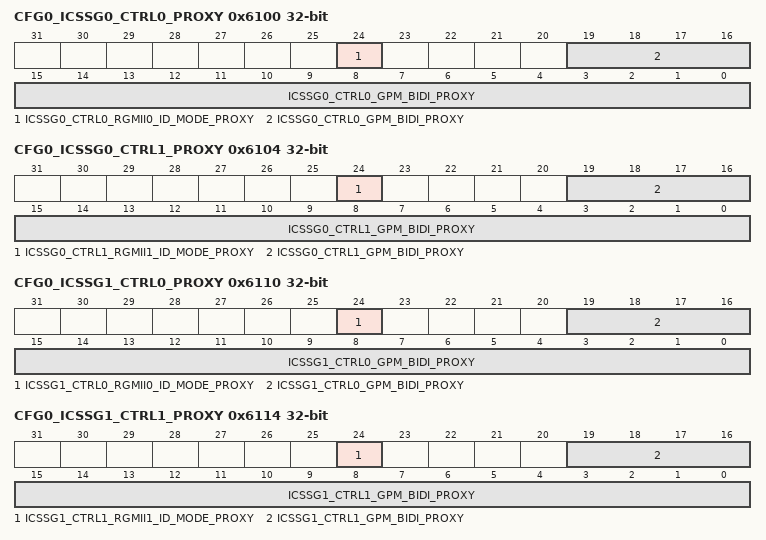
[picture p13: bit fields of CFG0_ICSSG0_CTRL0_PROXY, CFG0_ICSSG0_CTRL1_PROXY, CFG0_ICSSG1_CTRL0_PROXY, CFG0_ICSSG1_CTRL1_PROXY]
0x6100 CFG0_ICSSG0_CTRL0_PROXY
  [24] ICSSG0_CTRL0_RGMII0_ID_MODE_PROXY — Controls the ICSS_G0 RGMII0 port internal transmit delay
  [19:0] ICSSG0_CTRL0_GPM_BIDI_PROXY — Controls operation of the ICSS_G0 PRU0_GPO pins. Each bit n controls the corresponding PRG0_PRU0GPOn I/O
0x6104 CFG0_ICSSG0_CTRL1_PROXY
  [24] ICSSG0_CTRL1_RGMII1_ID_MODE_PROXY — Controls the ICSS_G0 RGMII1 port internal transmit delay
  [19:0] ICSSG0_CTRL1_GPM_BIDI_PROXY — Controls operation of the ICSS_G0 PRU1_GPO pins. Each bit n controls the corresponding PRG0_PRU1GPOn I/O
0x6110 CFG0_ICSSG1_CTRL0_PROXY
  [24] ICSSG1_CTRL0_RGMII0_ID_MODE_PROXY — Controls the ICSS_G1 RGMII0 port internal transmit delay
  [19:0] ICSSG1_CTRL0_GPM_BIDI_PROXY — Controls operation of the ICSS_G1 PRU0_GPO pins. Each bit n controls the corresponding PRG1_PRU0GPOn I/O
0x6114 CFG0_ICSSG1_CTRL1_PROXY
  [24] ICSSG1_CTRL1_RGMII1_ID_MODE_PROXY — Controls the ICSS_G1 RGMII1 port internal transmit delay
  [19:0] ICSSG1_CTRL1_GPM_BIDI_PROXY — Controls operation of the ICSS_G1 PRU1_GPO pins. Each bit n controls the corresponding PRG1_PRU1GPOn I/O
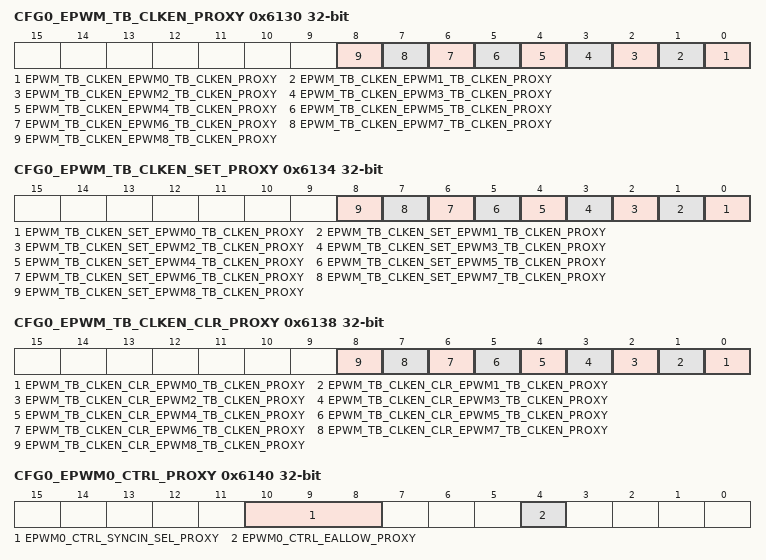
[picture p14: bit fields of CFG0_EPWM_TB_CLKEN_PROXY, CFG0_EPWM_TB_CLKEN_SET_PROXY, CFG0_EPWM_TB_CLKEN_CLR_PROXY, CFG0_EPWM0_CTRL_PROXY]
0x6130 CFG0_EPWM_TB_CLKEN_PROXY
  [n] EPWM_TB_CLKEN_EPWM{n}_TB_CLKEN_PROXY (n=0..8) — Activates Timebase Clock of EPWM{n} When Set
0x6134 CFG0_EPWM_TB_CLKEN_SET_PROXY access not given
  [n] EPWM_TB_CLKEN_SET_EPWM{n}_TB_CLKEN_PROXY (n=0..8) — Writing One Activates Timebase Clock of EPWM{n} (access R/W1TS)
0x6138 CFG0_EPWM_TB_CLKEN_CLR_PROXY access not given
  [n] EPWM_TB_CLKEN_CLR_EPWM{n}_TB_CLKEN_PROXY (n=0..8) — Writing One Deactivates Timebase Clock of EPWM{n} (access R/W1TC)
0x6140 CFG0_EPWM0_CTRL_PROXY
  [10:8] EPWM0_CTRL_SYNCIN_SEL_PROXY — Selects the source of the EPWM0 synchronization input
  [4] EPWM0_CTRL_EALLOW_PROXY — Activate write access to EPWM tripzone registers
0x6144 CFG0_EPWM1_CTRL_PROXY
  [4] EPWM1_CTRL_EALLOW_PROXY — Activate write access to EPWM tripzone registers
0x6148 CFG0_EPWM2_CTRL_PROXY
  [4] EPWM2_CTRL_EALLOW_PROXY — Activate write access to EPWM tripzone registers
0x614C CFG0_EPWM3_CTRL_PROXY
  [10:8] EPWM3_CTRL_SYNCIN_SEL_PROXY — Selects the source of the EPWM3 synchronization input
  [4] EPWM3_CTRL_EALLOW_PROXY — Activate write access to EPWM tripzone registers
0x6150 CFG0_EPWM4_CTRL_PROXY
  [4] EPWM4_CTRL_EALLOW_PROXY — Activate write access to EPWM tripzone registers
0x6154 CFG0_EPWM5_CTRL_PROXY
  [4] EPWM5_CTRL_EALLOW_PROXY — Activate write access to EPWM tripzone registers
0x6158 CFG0_EPWM6_CTRL_PROXY
  [10:8] EPWM6_CTRL_SYNCIN_SEL_PROXY — Selects the source of the EPWM6 synchronization input
  [4] EPWM6_CTRL_EALLOW_PROXY — Activate write access to EPWM tripzone registers
0x615C CFG0_EPWM7_CTRL_PROXY
  [4] EPWM7_CTRL_EALLOW_PROXY — Activate write access to EPWM tripzone registers
0x6160 CFG0_EPWM8_CTRL_PROXY
  [4] EPWM8_CTRL_EALLOW_PROXY — Activate write access to EPWM tripzone registers
0x6170 CFG0_SOCA_SEL_PROXY
  [1:0] SOCA_SEL_SOCA_SEL_PROXY — Selects the SOC A output source
0x6174 CFG0_SOCB_SEL_PROXY
  [1:0] SOCB_SEL_SOCB_SEL_PROXY — Selects the SOC B output source
{0x6180+4i} CFG0_EQEP{i}_CTRL_PROXY (i=0..2)
  [4:0] EQEP{i}_CTRL_SOCA_SEL_PROXY — Selects the source of SOCA input for EQEP{i}
0x61A0 CFG0_EQEP_STAT_PROXY ro
  [2] EQEP_STAT_PHASE_ERR2_PROXY — EQEP2 Phase error status
  [1] EQEP_STAT_PHASE_ERR1_PROXY — EQEP1 Phase error status
  [0] EQEP_STAT_PHASE_ERR0_PROXY — EQEP0 Phase error status
0x61B4 CFG0_SDIO1_CTRL_PROXY
  [4:0] SDIO1_CTRL_DRV_STR_PROXY — Selects the SDIO drive strength
0x6204 CFG0_TIMER1_CTRL_PROXY
  [8] TIMER1_CTRL_CASCADE_EN_PROXY — Activates cascading of TIMER1 to TIMER0
0x620C CFG0_TIMER3_CTRL_PROXY
  [8] TIMER3_CTRL_CASCADE_EN_PROXY — Activates cascading of TIMER3 to TIMER2
0x6214 CFG0_TIMER5_CTRL_PROXY
  [8] TIMER5_CTRL_CASCADE_EN_PROXY — Activates cascading of TIMER5 to TIMER4
0x621C CFG0_TIMER7_CTRL_PROXY
  [8] TIMER7_CTRL_CASCADE_EN_PROXY — Activates cascading of TIMER7 to TIMER6
0x6224 CFG0_TIMER9_CTRL_PROXY
  [8] TIMER9_CTRL_CASCADE_EN_PROXY — Activates cascading of TIMER9 to TIMER8
0x622C CFG0_TIMER11_CTRL_PROXY
  [8] TIMER11_CTRL_CASCADE_EN_PROXY — Activates cascading of TIMER11 to TIMER10
0x62E0 CFG0_I2C0_CTRL_PROXY
  [0] I2C0_CTRL_HS_MCS_EN_PROXY — HS Mode controller current source activate.
0x6700 CFG0_FSS_CTRL_PROXY
  [8] FSS_CTRL_S0_BOOT_SIZE_PROXY — Selects the size of the boot block to be used for the S0 (OSPI0) flash interface
  [5:0] FSS_CTRL_S0_BOOT_SEG_PROXY — Selects the boot block to be used for the S0 (OSPI0) flash interface. If the s0_boot_size is 128 MB then only bits [4:0] of this field are used. Care must be taken to account for the address translation as to not fall off or wrap the address of the flash. (e.g. if both ECC and authentication are activated for 64 MB boot, the highest valid block number is is 49, as sector 50 is only .2M Bytes in size.)
0x6710 CFG0_ADC0_CTRL_PROXY
  [16] ADC0_CTRL_GPI_MODE_EN_PROXY — Activates ADC0 data pins to be used as general purpose inputs when set. This signal is tied to the en_dig_test input of MCU_ADC0
  [4:0] ADC0_CTRL_TRIG_SEL_PROXY — Selects the source of the ADC hardware event trigger
0x6750 CFG0_DCC_STAT_PROXY ro
  [16] DCC_STAT_MCU_DCC0_INTR_DONE_PROXY — MCU_DCC0 Done Interrupt Status
  [n] DCC_STAT_DCC{n}_INTR_DONE_PROXY (n=0..5) — DCC{n} Done Interrupt Status
{0x7100+4i} CFG0_CLAIMREG_P1_R{i} (i=0..14)
  [31:0] CLAIMREG_P1_R{i} — Claim bits for Partition 1
0x8000 CFG0_OBSCLK0_CTRL reset 0x7
  [16] OBSCLK0_CTRL_CLK_DIV_LD — Load the output divider value
  [15:8] OBSCLK0_CTRL_CLK_DIV — OBSCLK0 output divider
  [3:0] OBSCLK0_CTRL_CLK_SEL — OBSCLK0 clock source selection.
0x8010 CFG0_CLKOUT_CTRL
  [4] CLKOUT_CTRL_CLK_EN — When set, activates CLKOUT output
  [0] CLKOUT_CTRL_CLK_SEL — Selects CLKOUT clock source
0x8030 CFG0_GTC_CLKSEL
  [2:0] GTC_CLKSEL_CLK_SEL — Selects the GTC timebase clock source
0x803C CFG0_EFUSE_CLKSEL
  [0] EFUSE_CLKSEL_CLK_SEL — Selects the clock source
0x8040 CFG0_ICSSG0_CLKSEL
  [18:16] ICSSG0_CLKSEL_IEP_CLKSEL — Selects the ICSSG0 IEP clock source
  [0] ICSSG0_CLKSEL_CORE_CLKSEL — Selects the ICSSG0 functional clock source
0x8044 CFG0_ICSSG1_CLKSEL
  [18:16] ICSSG1_CLKSEL_IEP_CLKSEL — Selects the ICSSG1 IEP clock source
  [0] ICSSG1_CLKSEL_CORE_CLKSEL — Selects the ICSSG1 functional clock source
{0x8060+4i} CFG0_MAIN_PLL{i}_CLKSEL (i=0..2)
  [31] MAIN_PLL{i}_CLKSEL_BYPASS_SW_OVRD — PLL Bypass warm reset software override
  [23] MAIN_PLL{i}_CLKSEL_BYP_WARM_RST — PLL bypass mode after warm reset.
0x8080 CFG0_MAIN_PLL8_CLKSEL reset 0x800000
  [31] MAIN_PLL8_CLKSEL_BYPASS_SW_OVRD — PLL Bypass warm reset software override
  [23] MAIN_PLL8_CLKSEL_BYP_WARM_RST — PLL bypass mode after warm reset.
0x8090 CFG0_MAIN_PLL12_CLKSEL reset 0x800000
  [31] MAIN_PLL12_CLKSEL_BYPASS_SW_OVRD — PLL Bypass warm reset software override
  [23] MAIN_PLL12_CLKSEL_BYP_WARM_RST — PLL bypass mode after warm reset.
0x8098 CFG0_MAIN_PLL14_CLKSEL reset 0x800000
  [31] MAIN_PLL14_CLKSEL_BYPASS_SW_OVRD — PLL Bypass warm reset software override
  [23] MAIN_PLL14_CLKSEL_BYP_WARM_RST — PLL bypass mode after warm reset.
0x8120 CFG0_PCIE0_CLKSEL
  [2:0] PCIE0_CLKSEL_CPTS_CLKSEL — Selects the clock source for the PCIE0 Common Platform Time Stamp module
0x8140 CFG0_CPSW_CLKSEL
  [3:0] CPSW_CLKSEL_CPTS_CLKSEL — Selects the clock source for the CPSW Ethernet switch Common Platform Time Stamp module
0x8150 CFG0_CPTS_CLKSEL
  [2:0] CPTS_CLKSEL_CPTS_CLKSEL — Selects the clock source for the SoC Common Platform Time Stamp module
0x8160 CFG0_EMMC0_CLKSEL
  [0] EMMC0_CLKSEL_EMMCSD0_REFCLK_SEL — eMMC XIN_CLK selection
0x8168 CFG0_EMMC1_CLKSEL reset 0x1
  [16] EMMC1_CLKSEL_EMMCSD1_IO_CLKLB_SEL — eMMC IO Clock Selection:
  [0] EMMC1_CLKSEL_EMMCSD1_REFCLK_SEL — eMMC XIN_CLK selection
0x8180 CFG0_GPMC_CLKSEL
  [0] GPMC_CLKSEL_CLK_SEL — Selects the GPMC clock source
0x8190 CFG0_USB0_CLKSEL
  [0] USB0_CLKSEL_REFCLK_SEL — Selects the clock source for the USB0 ref_clk.
{0x81B0+4i} CFG0_TIMER{i}_CLKSEL (i=0..11)
  [3:0] TIMER{i}_CLKSEL_CLK_SEL — Timer functional clock input select mux control (Reserved values default to HFOSC1_CLK)
{0x8200+4i} CFG0_SPI{i}_CLKSEL (i=0..4)
  [16] SPI{i}_CLKSEL_MSTR_LB_CLKSEL — Controller mode receive capture clock loopback selection
{0x8240+4i} CFG0_USART{i}_CLK_CTRL reset 0x3 (i=0..6)
  [16] USART{i}_CLK_CTRL_CLK_DIV_LD — Load the output divider value
  [1:0] USART{i}_CLK_CTRL_CLK_DIV — Selects the clock divider value. Supports divide values of 1 to 4 Default is /4. To load the new divider value the clk_div_ld bit must be cleared and then set to 1.
{0x8280+4i} CFG0_USART{i}_CLKSEL (i=0..6)
  [0] USART{i}_CLKSEL_CLK_SEL — Selects the clock source for UART{i}:
0x8380 CFG0_WWD0_CLKSEL
  [31] WWD0_CLKSEL_WRTLOCK — When set, locks WWD0_CLKSEL from further writes until the next module reset.
  [1:0] WWD0_CLKSEL_CLK_SEL — Windowed watchdog timer functional clock input select mux control
0x8384 CFG0_WWD1_CLKSEL
  [31] WWD1_CLKSEL_WRTLOCK — When set, locks WWD1_CLKSEL from further writes until the next module reset.
  [1:0] WWD1_CLKSEL_CLK_SEL — Windowed watchdog timer functional clock input select mux control
{0x8380+4i} CFG0_WWD{i}_CLKSEL (i=8..11)
  [31] WWD{i}_CLKSEL_WRTLOCK — When set, locks WWD{i}_CLKSEL from further writes until the next module reset.
  [1:0] WWD{i}_CLKSEL_CLK_SEL — Windowed watchdog timer functional clock input select mux control
0x8400 CFG0_SERDES0_CLKSEL
  [1:0] SERDES0_CLKSEL_CORE_REFCLK_SEL — Selects the source for the core_refclk input
0x8480 CFG0_MCAN0_CLKSEL
  [1:0] MCAN0_CLKSEL_CLK_SEL — MAIN MCAN_CLK selection
0x8484 CFG0_MCAN1_CLKSEL
  [1:0] MCAN1_CLKSEL_CLK_SEL — MAIN MCAN_CLK selection
0x8500 CFG0_OSPI0_CLKSEL
  [4] OSPI0_CLKSEL_LOOPCLK_SEL — OBSPI0 Loopback clock source
  [0] OSPI0_CLKSEL_CLK_SEL — OSPI0 reference clock selection
0x8510 CFG0_ADC0_CLKSEL
  [1:0] ADC0_CLKSEL_CLK_SEL — Selects the sampling clock source for ADC0
{0x9100+4i} CFG0_CLAIMREG_P2_R{i}_READONLY ro (i=0..10)
  [31:0] CLAIMREG_P2_R{i}_READONLY — Claim bits for Partition 2
0xA000 CFG0_OBSCLK0_CTRL_PROXY reset 0x7
  [16] OBSCLK0_CTRL_CLK_DIV_LD_PROXY — Load the output divider value
  [15:8] OBSCLK0_CTRL_CLK_DIV_PROXY — OBSCLK0 output divider
  [3:0] OBSCLK0_CTRL_CLK_SEL_PROXY — OBSCLK0 clock source selection.
0xA010 CFG0_CLKOUT_CTRL_PROXY
  [4] CLKOUT_CTRL_CLK_EN_PROXY — When set, activates CLKOUT output
  [0] CLKOUT_CTRL_CLK_SEL_PROXY — Selects CLKOUT clock source
0xA030 CFG0_GTC_CLKSEL_PROXY
  [2:0] GTC_CLKSEL_CLK_SEL_PROXY — Selects the GTC timebase clock source
0xA03C CFG0_EFUSE_CLKSEL_PROXY
  [0] EFUSE_CLKSEL_CLK_SEL_PROXY — Selects the clock source
0xA040 CFG0_ICSSG0_CLKSEL_PROXY
  [18:16] ICSSG0_CLKSEL_IEP_CLKSEL_PROXY — Selects the ICSSG0 IEP clock source
  [0] ICSSG0_CLKSEL_CORE_CLKSEL_PROXY — Selects the ICSSG0 functional clock source
0xA044 CFG0_ICSSG1_CLKSEL_PROXY
  [18:16] ICSSG1_CLKSEL_IEP_CLKSEL_PROXY — Selects the ICSSG1 IEP clock source
  [0] ICSSG1_CLKSEL_CORE_CLKSEL_PROXY — Selects the ICSSG1 functional clock source
{0xA060+4i} CFG0_MAIN_PLL{i}_CLKSEL_PROXY (i=0..2)
  [31] MAIN_PLL{i}_CLKSEL_BYPASS_SW_OVRD_PROXY — PLL Bypass warm reset software override
  [23] MAIN_PLL{i}_CLKSEL_BYP_WARM_RST_PROXY — PLL bypass mode after warm reset.
0xA080 CFG0_MAIN_PLL8_CLKSEL_PROXY reset 0x800000
  [31] MAIN_PLL8_CLKSEL_BYPASS_SW_OVRD_PROXY — PLL Bypass warm reset software override
  [23] MAIN_PLL8_CLKSEL_BYP_WARM_RST_PROXY — PLL bypass mode after warm reset.
0xA090 CFG0_MAIN_PLL12_CLKSEL_PROXY reset 0x800000
  [31] MAIN_PLL12_CLKSEL_BYPASS_SW_OVRD_PROXY — PLL Bypass warm reset software override
  [23] MAIN_PLL12_CLKSEL_BYP_WARM_RST_PROXY — PLL bypass mode after warm reset.
0xA098 CFG0_MAIN_PLL14_CLKSEL_PROXY reset 0x800000
  [31] MAIN_PLL14_CLKSEL_BYPASS_SW_OVRD_PROXY — PLL Bypass warm reset software override
  [23] MAIN_PLL14_CLKSEL_BYP_WARM_RST_PROXY — PLL bypass mode after warm reset.
0xA120 CFG0_PCIE0_CLKSEL_PROXY
  [2:0] PCIE0_CLKSEL_CPTS_CLKSEL_PROXY — Selects the clock source for the PCIE0 Common Platform Time Stamp module
0xA140 CFG0_CPSW_CLKSEL_PROXY
  [3:0] CPSW_CLKSEL_CPTS_CLKSEL_PROXY — Selects the clock source for the CPSW Ethernet switch Common Platform Time Stamp module
0xA150 CFG0_CPTS_CLKSEL_PROXY
  [2:0] CPTS_CLKSEL_CPTS_CLKSEL_PROXY — Selects the clock source for the SoC Common Platform Time Stamp module
0xA160 CFG0_EMMC0_CLKSEL_PROXY
  [0] EMMC0_CLKSEL_EMMCSD0_REFCLK_SEL_PROXY — eMMC XIN_CLK selection
0xA168 CFG0_EMMC1_CLKSEL_PROXY reset 0x1
  [16] EMMC1_CLKSEL_EMMCSD1_IO_CLKLB_SEL_PROXY — eMMC IO Clock Selection:
  [0] EMMC1_CLKSEL_EMMCSD1_REFCLK_SEL_PROXY — eMMC XIN_CLK selection
0xA180 CFG0_GPMC_CLKSEL_PROXY
  [0] GPMC_CLKSEL_CLK_SEL_PROXY — Selects the GPMC clock source
0xA190 CFG0_USB0_CLKSEL_PROXY
  [0] USB0_CLKSEL_REFCLK_SEL_PROXY — Selects the clock source for the USB0 ref_clk.
{0xA1B0+4i} CFG0_TIMER{i}_CLKSEL_PROXY (i=0..11)
  [3:0] TIMER{i}_CLKSEL_CLK_SEL_PROXY — Timer functional clock input select mux control (Reserved values default to HFOSC1_CLK)
{0xA200+4i} CFG0_SPI{i}_CLKSEL_PROXY (i=0..4)
  [16] SPI{i}_CLKSEL_MSTR_LB_CLKSEL_PROXY — Controller mode receive capture clock loopback selection
{0xA240+4i} CFG0_USART{i}_CLK_CTRL_PROXY reset 0x3 (i=0..6)
  [16] USART{i}_CLK_CTRL_CLK_DIV_LD_PROXY — Load the output divider value
  [1:0] USART{i}_CLK_CTRL_CLK_DIV_PROXY — Selects the clock divider value. Supports divide values of 1 to 4 Default is /4. To load the new divider value the clk_div_ld bit must be cleared and then set to 1.
{0xA280+4i} CFG0_USART{i}_CLKSEL_PROXY (i=0..6)
  [0] USART{i}_CLKSEL_CLK_SEL_PROXY — Selects the clock source for UART{i}:
0xA380 CFG0_WWD0_CLKSEL_PROXY
  [31] WWD0_CLKSEL_WRTLOCK_PROXY — When set, locks WWD0_CLKSEL from further writes until the next module reset.
  [1:0] WWD0_CLKSEL_CLK_SEL_PROXY — Windowed watchdog timer functional clock input select mux control
0xA384 CFG0_WWD1_CLKSEL_PROXY
  [31] WWD1_CLKSEL_WRTLOCK_PROXY — When set, locks WWD1_CLKSEL from further writes until the next module reset.
  [1:0] WWD1_CLKSEL_CLK_SEL_PROXY — Windowed watchdog timer functional clock input select mux control
{0xA380+4i} CFG0_WWD{i}_CLKSEL_PROXY (i=8..11)
  [31] WWD{i}_CLKSEL_WRTLOCK_PROXY — When set, locks WWD{i}_CLKSEL from further writes until the next module reset.
  [1:0] WWD{i}_CLKSEL_CLK_SEL_PROXY — Windowed watchdog timer functional clock input select mux control
0xA400 CFG0_SERDES0_CLKSEL_PROXY
  [1:0] SERDES0_CLKSEL_CORE_REFCLK_SEL_PROXY — Selects the source for the core_refclk input
0xA480 CFG0_MCAN0_CLKSEL_PROXY
  [1:0] MCAN0_CLKSEL_CLK_SEL_PROXY — MAIN MCAN_CLK selection
0xA484 CFG0_MCAN1_CLKSEL_PROXY
  [1:0] MCAN1_CLKSEL_CLK_SEL_PROXY — MAIN MCAN_CLK selection
0xA500 CFG0_OSPI0_CLKSEL_PROXY
  [4] OSPI0_CLKSEL_LOOPCLK_SEL_PROXY — OBSPI0 Loopback clock source
  [0] OSPI0_CLKSEL_CLK_SEL_PROXY — OSPI0 reference clock selection
0xA510 CFG0_ADC0_CLKSEL_PROXY
  [1:0] ADC0_CLKSEL_CLK_SEL_PROXY — Selects the sampling clock source for ADC0
{0xB100+4i} CFG0_CLAIMREG_P2_R{i} (i=0..10)
  [31:0] CLAIMREG_P2_R{i} — Claim bits for Partition 2
0xC320 CFG0_FUSE_CRC_STAT ro
  [n] FUSE_CRC_STAT_CRC_ERR_{n} (n=1..7) — Indicates eFuse CRC error on chain {n}
0xC400 CFG0_PBIST_EN
  [8] PBIST_EN_PCIE0 — Activates PBIST Access to PCIE0 Memories
  [4] PBIST_EN_USB0 — Activates PBIST Access to USB0 Memories
  [1] PBIST_EN_EMMC1 — Activates PBIST Access to MMC1 Memories
  [0] PBIST_EN_EMMC0 — Activates PBIST Access to MMC0 Memories
{0xD100+4i} CFG0_CLAIMREG_P3_R{i}_READONLY ro (i=0..8)
  [31:0] CLAIMREG_P3_R{i}_READONLY — Claim bits for Partition 3
0xE320 CFG0_FUSE_CRC_STAT_PROXY ro
  [n] FUSE_CRC_STAT_CRC_ERR_{n}_PROXY (n=1..7) — Indicates eFuse CRC error on chain {n}
0xE400 CFG0_PBIST_EN_PROXY
  [8] PBIST_EN_PCIE0_PROXY — Activates PBIST Access to PCIE0 Memories
  [4] PBIST_EN_USB0_PROXY — Activates PBIST Access to USB0 Memories
  [1] PBIST_EN_EMMC1_PROXY — Activates PBIST Access to MMC1 Memories
  [0] PBIST_EN_EMMC0_PROXY — Activates PBIST Access to MMC0 Memories
{0xF100+4i} CFG0_CLAIMREG_P3_R{i} (i=0..8)
  [31:0] CLAIMREG_P3_R{i} — Claim bits for Partition 3
{0x11100+4i} CFG0_CLAIMREG_P4_R{i}_READONLY ro (i=0..12)
  [31:0] CLAIMREG_P4_R{i}_READONLY — Claim bits for Partition 4
{0x13100+4i} CFG0_CLAIMREG_P4_R{i} (i=0..12)
  [31:0] CLAIMREG_P4_R{i} — Claim bits for Partition 4
0x14000 CFG0_CHNG_DDR4_FSP_REQ
  [8] CHNG_DDR4_FSP_REQ_REQ — Initiate FSP frequency change
  [1:0] CHNG_DDR4_FSP_REQ_REQ_TYPE — Frequency request type
0x14004 CFG0_CHNG_DDR4_FSP_ACK ro
  [7] CHNG_DDR4_FSP_ACK_ACK — Frequency change acknowledge.
  [0] CHNG_DDR4_FSP_ACK_ERROR — Frequency change error
0x14080 CFG0_DDR4_FSP_CLKCHNG_REQ ro
  [7] DDR4_FSP_CLKCHNG_REQ_REQ — DDR Controller FSP clock change request
  [1:0] DDR4_FSP_CLKCHNG_REQ_REQ_TYPE — Frequency request type
0x140C0 CFG0_DDR4_FSP_CLKCHNG_ACK
  [0] DDR4_FSP_CLKCHNG_ACK_ACK — DDR FSP clock change ackowledge
0x15100 CFG0_CLAIMREG_P5_R0_READONLY ro
  [31:0] CLAIMREG_P5_R0_READONLY — Claim bits for Partition 5
0x15104 CFG0_CLAIMREG_P5_R1_READONLY ro
  [31:0] CLAIMREG_P5_R1_READONLY — Claim bits for Partition 5
0x16000 CFG0_CHNG_DDR4_FSP_REQ_PROXY
  [8] CHNG_DDR4_FSP_REQ_REQ_PROXY — Initiate FSP frequency change
  [1:0] CHNG_DDR4_FSP_REQ_REQ_TYPE_PROXY — Frequency request type
0x16004 CFG0_CHNG_DDR4_FSP_ACK_PROXY ro
  [7] CHNG_DDR4_FSP_ACK_ACK_PROXY — Frequency change acknowledge.
  [0] CHNG_DDR4_FSP_ACK_ERROR_PROXY — Frequency change error
0x16080 CFG0_DDR4_FSP_CLKCHNG_REQ_PROXY ro
  [7] DDR4_FSP_CLKCHNG_REQ_REQ_PROXY — DDR Controller FSP clock change request
  [1:0] DDR4_FSP_CLKCHNG_REQ_REQ_TYPE_PROXY — Frequency request type
0x160C0 CFG0_DDR4_FSP_CLKCHNG_ACK_PROXY
  [0] DDR4_FSP_CLKCHNG_ACK_ACK_PROXY — DDR FSP clock change ackowledge
0x17100 CFG0_CLAIMREG_P5_R0
  [31:0] CLAIMREG_P5_R0 — Claim bits for Partition 5
0x17104 CFG0_CLAIMREG_P5_R1
  [31:0] CLAIMREG_P5_R1 — Claim bits for Partition 5
0x18170 CFG0_RST_CTRL reset 0x200FF
  [18] RST_CTRL_MAIN_RESET_ISO_DONE_Z — Main Domain CPUs can set this bit to block warm reset in the main domain which is useful when the Main domain may be accessing
  [17] RST_CTRL_MAIN_ESM_ERROR_RST_EN_Z — Deactivate Reset of Main by ESM
  [16] RST_CTRL_DMSC_COLD_RESET_EN_Z — Deactivate Reset of Main by DMSC
  [7:4] RST_CTRL_SW_MAIN_POR — Causes Main Domain Power On Reset when set to 4'b0110, Bits will reset to 4'b1111
  [3:0] RST_CTRL_SW_MAIN_WARMRST — Causes Main Domain Warm Reset when set to 4'b0110, Bits will reset to 4'b1111
0x18174 CFG0_RST_STAT ro
  [0] RST_STAT_MCU_RESET_ISO_DONE_Z — is an outstanding warm reset request for the main domain. Once notified, MCU needs to finish any outstanding
0x18178 CFG0_RST_SRC ro
  [31] RST_SRC_SAFETY_ERROR — Reset Caused by MCU ESM Error
  [30] RST_SRC_MAIN_ESM_ERROR — Reset Caused by Main ESM Error
  [25] RST_SRC_SW_MAIN_POR_FROM_MAIN — Software Main Power On Reset From MAIN CTRL MMR
  [24] RST_SRC_SW_MAIN_POR_FROM_MCU — Software Main Power On Reset From MCU CTRL MMR
  [21] RST_SRC_SW_MAIN_WARMRST_FROM_MAIN — Software Main Warm Reset from MAIN CTRL MMR
  [20] RST_SRC_SW_MAIN_WARMRST_FROM_MCU — Software Main Warm Reset From MCU CTRL MMR
  [16] RST_SRC_SW_MCU_WARMRST — Software Warm Reset
  [13] RST_SRC_WARM_OUT_RST — DMSC Warm Reset
  [12] RST_SRC_COLD_OUT_RST — DMSC Cold Reset
  [8] RST_SRC_DEBUG_RST — Debug Subsystem Initiated Reset
  [4] RST_SRC_THERMAL_RST — Thermal Reset
  [2] RST_SRC_MAIN_RESET_REQ — Main Reset Pin
  [0] RST_SRC_MCU_RESET_PIN — Rest Caused by MCU Reset Pin
0x1817C CFG0_RST_MAGIC_WORD ro
  [31:0] RST_MAGIC_WORD_MCU_MAGIC_WORD — Magic Word Indicating Status of MCU Subsystem Boot
{0x19100+4i} CFG0_CLAIMREG_P6_R{i}_READONLY ro (i=0..2)
  [31:0] CLAIMREG_P6_R{i}_READONLY — Claim bits for Partition 6
0x1A170 CFG0_RST_CTRL_PROXY reset 0x200FF
  [18] RST_CTRL_MAIN_RESET_ISO_DONE_Z_PROXY — Main Domain CPUs can set this bit to block warm reset in the main domain which is useful when the Main domain may be accessing
  [17] RST_CTRL_MAIN_ESM_ERROR_RST_EN_Z_PROXY — Deactivate Reset of Main by ESM
  [16] RST_CTRL_DMSC_COLD_RESET_EN_Z_PROXY — Deactivate Reset of Main by DMSC
  [7:4] RST_CTRL_SW_MAIN_POR_PROXY — Causes Main Domain Power On Reset when set to 4'b0110, Bits will reset to 4'b1111
  [3:0] RST_CTRL_SW_MAIN_WARMRST_PROXY — Causes Main Domain Warm Reset when set to 4'b0110, Bits will reset to 4'b1111
0x1A174 CFG0_RST_STAT_PROXY ro
  [0] RST_STAT_MCU_RESET_ISO_DONE_Z_PROXY — is an outstanding warm reset request for the main domain. Once notified, MCU needs to finish any outstanding
0x1A178 CFG0_RST_SRC_PROXY ro
  [31] RST_SRC_SAFETY_ERROR_PROXY — Reset Caused by MCU ESM Error
  [30] RST_SRC_MAIN_ESM_ERROR_PROXY — Reset Caused by Main ESM Error
  [25] RST_SRC_SW_MAIN_POR_FROM_MAIN_PROXY — Software Main Power On Reset From MAIN CTRL MMR
  [24] RST_SRC_SW_MAIN_POR_FROM_MCU_PROXY — Software Main Power On Reset From MCU CTRL MMR
  [21] RST_SRC_SW_MAIN_WARMRST_FROM_MAIN_PROXY — Software Main Warm Reset from MAIN CTRL MMR
  [20] RST_SRC_SW_MAIN_WARMRST_FROM_MCU_PROXY — Software Main Warm Reset From MCU CTRL MMR
  [16] RST_SRC_SW_MCU_WARMRST_PROXY — Software Warm Reset
  [13] RST_SRC_WARM_OUT_RST_PROXY — DMSC Warm Reset
  [12] RST_SRC_COLD_OUT_RST_PROXY — DMSC Cold Reset
  [8] RST_SRC_DEBUG_RST_PROXY — Debug Subsystem Initiated Reset
  [4] RST_SRC_THERMAL_RST_PROXY — Thermal Reset
  [2] RST_SRC_MAIN_RESET_REQ_PROXY — Main Reset Pin
  [0] RST_SRC_MCU_RESET_PIN_PROXY — Rest Caused by MCU Reset Pin
0x1A17C CFG0_RST_MAGIC_WORD_PROXY ro
  [31:0] RST_MAGIC_WORD_MCU_MAGIC_WORD_PROXY — Magic Word Indicating Status of MCU Subsystem Boot
{0x1B100+4i} CFG0_CLAIMREG_P6_R{i} (i=0..2)
  [31:0] CLAIMREG_P6_R{i} — Claim bits for Partition 6
